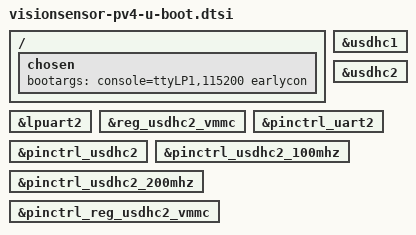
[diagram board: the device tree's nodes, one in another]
// SPDX-License-Identifier: GPL-2.0+
/*
 * Copyright 2024 NXP
 */

/ {
	chosen {
		bootargs = "console=ttyLP1,115200 earlycon";
	};
};

/*&scmi_iomuxc {
	pinctrl-names = "default";
	pinctrl-0 = <&pinctrl_hog>;

	pinctrl_hog: hoggrp {
		bootph-all;
		bootph-pre-ram;

		fsl,pins = <
			IMX95_PAD_XSPI1_SCLK__GPIO5_IO_BIT9			0x3fe
			IMX95_PAD_CCM_CLKO1__GPIO3_IO_BIT26			0x3fe
			IMX95_PAD_CCM_CLKO2__GPIO3_IO_BIT27			0x3fe
		>;
	};
};*/

&lpuart2 {
	bootph-pre-ram;
};

&reg_usdhc2_vmmc {
	bootph-pre-ram;
};

&usdhc1 {
	bootph-pre-ram;
};

&usdhc2 {
	bootph-pre-ram;
};

&pinctrl_uart2 {
	bootph-pre-ram;
};

&pinctrl_usdhc2 {
	bootph-pre-ram;
};

&pinctrl_usdhc2_100mhz {
	bootph-pre-ram;
};

&pinctrl_usdhc2_200mhz {
	bootph-pre-ram;
};

/*&pinctrl_usdhc2_gpio {
	bootph-pre-ram;
};*/

&pinctrl_reg_usdhc2_vmmc {
	bootph-pre-ram;
};
